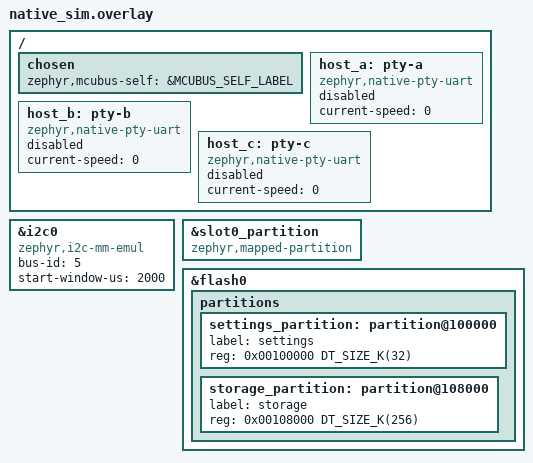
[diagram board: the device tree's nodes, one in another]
/*
 * Copyright (c) 2026 Christoph Jans <jans.christoph@gmail.com>
 *
 * SPDX-License-Identifier: Apache-2.0
 */

/* native_sim ships &i2c0 as a stock emulated controller; here it is the
 * multi-master port (ws-zephyr/drivers/i2c/i2c_mm_emul.c), wired to the other
 * MCUs, on bus 5.
 * Which MCU an image is comes from CMake: MCUBUS_SELF_LABEL is mcu_<NODE>.
 */

/ {
	chosen {
		zephyr,mcubus-self = &MCUBUS_SELF_LABEL;
	};

	/* The gateway's ports to the laptop (gateway.overlay enables them):
	 * "pty-a connected to pseudotty: /dev/pts/N"
	 */
	host_a: pty-a {
		compatible = "zephyr,native-pty-uart";
		current-speed = <0>;
		status = "disabled";
	};

	host_b: pty-b {
		compatible = "zephyr,native-pty-uart";
		current-speed = <0>;
		status = "disabled";
	};

	host_c: pty-c {
		compatible = "zephyr,native-pty-uart";
		current-speed = <0>;
		status = "disabled";
	};
};

&i2c0 {
	compatible = "zephyr,i2c-mm-emul";
	bus-id = <5>;
	start-window-us = <2000>;

#include "../mcubus_nodes.dtsi"
};

/* Slot 0 as a mapped partition: the img group of MCUmgr finds the running image
 * by the chosen code partition
 */
&slot0_partition {
	compatible = "zephyr,mapped-partition";
};

/* A board's partitions, after the stock ones, which end at 1 MiB; the stock
 * storage_partition goes, so that there is one storage
 */
/delete-node/ &storage_partition;

&flash0 {
	partitions {
		settings_partition: partition@100000 {
			label = "settings";
			reg = <0x00100000 DT_SIZE_K(32)>;
		};

		storage_partition: partition@108000 {
			label = "storage";
			reg = <0x00108000 DT_SIZE_K(256)>;
		};
	};
};
